AUTOSAR XML (schema 4-2-2)
standard types defined: boolean, uint8, uint32, uint16, sint8, dtRef_VOID, dtRef_const_VOID, boolean_CompuMethod, sint32
package /Components
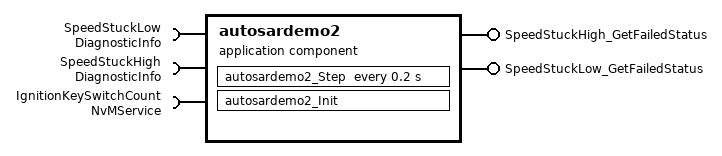
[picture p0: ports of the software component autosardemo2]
  application sw component type autosardemo2
    provide port SpeedStuckHigh_GetFailedStatus: nonqueued-sender-com-spec{data-element=SpeedStuckHigh_GetFailedStatus, init-value=0}, provided-interface=SpeedStuckHigh_GetFailedStatus
    provide port SpeedStuckLow_GetFailedStatus: nonqueued-sender-com-spec{data-element=SpeedStuckLow_GetFailedStatus, init-value=0}, provided-interface=SpeedStuckLow_GetFailedStatus
    require port SpeedStuckLow: required-interface=DiagnosticInfo
    require port SpeedStuckHigh: required-interface=DiagnosticInfo
    require port IgnitionKeySwitchCount: required-interface=NvMService
    behavior autosardemo2_IB: handle-termination-and-restart=NO-SUPPORT
      timing event Event_autosardemo2_Step: start-on-event=autosardemo2_Step, period=0.2
      runnable autosardemo2_Init
      runnable autosardemo2_Step
        data-write-access:
          access OUT_SpeedStuckHigh_GetFailedStatus_SpeedStuckHigh_GetFailedStatus: accessed-variable=SpeedStuckHigh_GetFailedStatus.SpeedStuckHigh_GetFailedStatus
          access OUT_SpeedStuckLow_GetFailedStatus_SpeedStuckLow_GetFailedStatus: accessed-variable=SpeedStuckLow_GetFailedStatus.SpeedStuckLow_GetFailedStatus
        sync call SC_SpeedStuckHigh_GetEventFailed: operation=SpeedStuckHigh.GetEventFailed, timeout=1.0E-06
        sync call SC_SpeedStuckLow_GetEventFailed: operation=SpeedStuckLow.GetEventFailed, timeout=1.0E-06
package /Components/SwcImplementations
  swc implementation autosardemo2_Impl: programming-language=C, sw-version=1.12.1, used-code-generator=Embedded Coder 24.1 (R2024a) 19-Nov-2023, vendor-id=0, behavior=autosardemo2_IB
    code-descriptors:
      code Code
        artifact-descriptors:
          short-label=GetStatus_c, category=SWSRC
          short-label=MWDSP_EPH_F_B_c, category=SWSRC
          short-label=rt_roundd_c, category=SWSRC
          short-label=GetStatus_h, category=SWHDR
          short-label=GetStatus_private_h, category=SWHDR
          short-label=GetStatus_types_h, category=SWHDR
          short-label=MWDSP_EPH_F_B_h, category=SWHDR
          short-label=rt_roundd_h, category=SWHDR
    resource consumption RsrcCons_GetStatus
package /Components
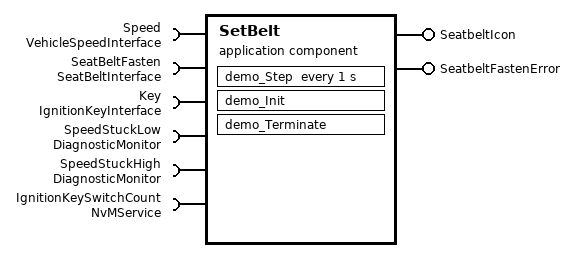
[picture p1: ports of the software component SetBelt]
  application sw component type SetBelt
    require port Speed: nonqueued-receiver-com-spec{data-element=Speed, init-value=0}, required-interface=VehicleSpeedInterface
    require port SeatBeltFasten: nonqueued-receiver-com-spec{data-element=SeatBeltFasten, init-value=0}, required-interface=SeatBeltInterface
    require port Key: nonqueued-receiver-com-spec{data-element=Key, init-value=OFF}, required-interface=IgnitionKeyInterface
    provide port SeatbeltIcon: nonqueued-sender-com-spec{data-element=SeatbeltIcon, init-value=0}, provided-interface=SeatbeltIcon
    provide port SeatbeltFastenError: nonqueued-sender-com-spec{data-element=SeatbeltFastenError, init-value=0}, provided-interface=SeatbeltFastenError
    require port SpeedStuckLow: required-interface=DiagnosticMonitor
    require port SpeedStuckHigh: required-interface=DiagnosticMonitor
    require port IgnitionKeySwitchCount: required-interface=NvMService
    behavior demo_IB: handle-termination-and-restart=NO-SUPPORT
      timing event Event_demo_Step: start-on-event=demo_Step, period=1
      runnable demo_Init
        async call SC_IgnitionKeySwitchCount_ReadBlock: operation=IgnitionKeySwitchCount.ReadBlock, timeout=1
      runnable demo_Step
        data-read-access:
          access IN_Key_Key: accessed-variable=Key.Key
          access IN_SeatBeltFasten_SeatBeltFasten: accessed-variable=SeatBeltFasten.SeatBeltFasten
          access IN_Speed_Speed: accessed-variable=Speed.Speed
        data-write-access:
          access OUT_SeatbeltIcon_SeatbeltIcon: accessed-variable=SeatbeltIcon.SeatbeltIcon
          access OUT_SeatbeltFastenError_SeatbeltFastenError: accessed-variable=SeatbeltFastenError.SeatbeltFastenError
        sync call SC_SpeedStuckHigh_SetEventStatus: operation=SpeedStuckHigh.SetEventStatus, timeout=1.0E-06
        sync call SC_SpeedStuckLow_SetEventStatus: operation=SpeedStuckLow.SetEventStatus, timeout=1.0E-06
        async call SC_IgnitionKeySwitchCount_WriteBlock: operation=IgnitionKeySwitchCount.WriteBlock, timeout=1
      runnable demo_Terminate
        async call SC_IgnitionKeySwitchCount_WriteBlock: operation=IgnitionKeySwitchCount.WriteBlock, timeout=1
package /Components/SwcImplementations
  swc implementation demo_Impl: programming-language=C, sw-version=1.41.1, used-code-generator=Embedded Coder 24.1 (R2024a) 19-Nov-2023, vendor-id=0, behavior=demo_IB
    code-descriptors:
      code Code
        artifact-descriptors:
          short-label=MWDSP_EPH_F_B_c, category=SWSRC
          short-label=SeatBelt_c, category=SWSRC
          short-label=rt_roundd_c, category=SWSRC
          short-label=MWDSP_EPH_F_B_h, category=SWHDR
          short-label=SeatBelt_h, category=SWHDR
          short-label=SeatBelt_private_h, category=SWHDR
          short-label=SeatBelt_types_h, category=SWHDR
          short-label=rt_roundd_h, category=SWHDR
    resource consumption RsrcCons_SetBelt
package /DataTypes
  8 x impl type:
    Dem_DebouncingStateType: implementation-data-type=uint8
    Dem_DTCFormatType: compu {0=DEM_DTC_FORMAT_OBD, 1=DEM_DTC_FORMAT_UDS, 2=DEM_DTC_FORMAT_J1939}, implementation-data-type=uint8
    Dem_MaxDataValueType: implementation-data-type=uint8
    Dem_UdsStatusByteType: implementation-data-type=uint8
    NvM_RequestResultType: compu {0=NVM_REQ_OK, 1=NVM_REQ_NOT_OK, 2=NVM_REQ_PENDING, 3=NVM_REQ_INTEGRITY_FAILED, 4=NVM_REQ_BLOCK_SKIPPED, 5=NVM_REQ_NV_INVALIDATED, 6=NVM_REQ_CANCELED, 8=NVM_REQ_RESTORED_FROM_DEFAULTS}, implementation-data-type=uint8
    enState_IgnitionKey: category=VALUE, base-type=sint32, compu {0=OFF, 1=ACC, 2=ON, 3=CRANK}
    Dem_DebounceResetStatusType: compu {0=DEM_DEBOUNCE_STATUS_FREEZE, 1=DEM_DEBOUNCE_STATUS_RESET}, implementation-data-type=uint8
    Dem_EventStatusType: compu {0=DEM_EVENT_STATUS_PASSED, 1=DEM_EVENT_STATUS_FAILED, 2=DEM_EVENT_STATUS_PREPASSED, 3=DEM_EVENT_STATUS_PREFAILED, 4=DEM_EVENT_STATUS_FDC_THRESHOLD_REACHED}, implementation-data-type=uint8
package /DataTypes/SwAddrMethods
  sw addr method CODE: section-type=CODE
  sw addr method CONST: section-type=CONST
  sw addr method VAR: section-type=VAR
package /DataTypes/Units
  unit NoUnit: factor-si-to-unit=1, offset-si-to-unit=0
package /Interfaces
  5 x sender receiver interface:
    SpeedStuckHigh_GetFailedStatus
      data SpeedStuckHigh_GetFailedStatus: category=VALUE, sw-calibration-access=READ-ONLY, type=boolean
    SpeedStuckLow_GetFailedStatus
      data SpeedStuckLow_GetFailedStatus: category=VALUE, sw-calibration-access=READ-ONLY, type=boolean
    IgnitionKeySwitchCount_ReadBlock
      data IgnitionKeySwitchCount_ReadBlock: sw-calibration-access=READ-ONLY
    SeatbeltIcon
      data SeatbeltIcon: category=VALUE, sw-calibration-access=READ-ONLY, type=boolean
    SeatbeltFastenError
      data SeatbeltFastenError: category=VALUE, sw-calibration-access=READ-ONLY, type=boolean
  client server interface CheckStatus
  sender receiver interface VehicleSpeedInterface
    data Speed: category=VALUE, sw-calibration-access=READ-WRITE, type=DataTypes/uint16
  sender receiver interface SeatBeltInterface
    data SeatBeltFasten: category=VALUE, sw-calibration-access=READ-WRITE, type=boolean
  sender receiver interface IgnitionKeyInterface
    data Key: category=VALUE, sw-calibration-access=READ-WRITE, type=enState_IgnitionKey
package /Timing
  vfb timing untitled_timing: component=untitled
    timing-requirements:
      execution order constraint EOC: base-composition=untitled
        ordered-elements:
          eoc executable entity ref Model_autosardemo2_Step: component=Model, executable=autosardemo2_Step, successor=Model1_demo_Step
          eoc executable entity ref Model1_demo_Step: component=Model1, executable=demo_Step
package /Components
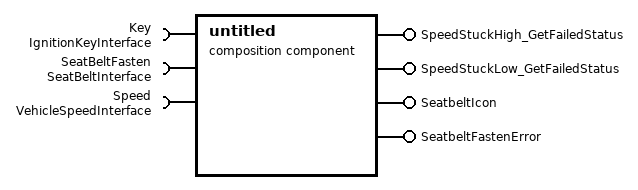
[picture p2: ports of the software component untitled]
  composition sw component type untitled
    require port Key: required-interface=IgnitionKeyInterface
    require port SeatBeltFasten: required-interface=SeatBeltInterface
    require port Speed: required-interface=VehicleSpeedInterface
    4 x provide port:
      SpeedStuckHigh_GetFailedStatus: provided-interface=SpeedStuckHigh_GetFailedStatus
      SpeedStuckLow_GetFailedStatus: provided-interface=SpeedStuckLow_GetFailedStatus
      SeatbeltIcon: provided-interface=SeatbeltIcon
      SeatbeltFastenError: provided-interface=SeatbeltFastenError
    component Model1: type=SetBelt
    component Model: type=autosardemo2
    delegate Model.SpeedStuckHigh_GetFailedStatus <-> outer port untitled/SpeedStuckHigh_GetFailedStatus
    delegate Model.SpeedStuckLow_GetFailedStatus <-> outer port untitled/SpeedStuckLow_GetFailedStatus
    delegate Model1.SeatbeltIcon <-> outer port untitled/SeatbeltIcon
    delegate Model1.SeatbeltFastenError <-> outer port untitled/SeatbeltFastenError
    delegate Model1.Key <-> outer port untitled/Key
    delegate Model1.SeatBeltFasten <-> outer port untitled/SeatBeltFasten
    delegate Model1.Speed <-> outer port untitled/Speed
